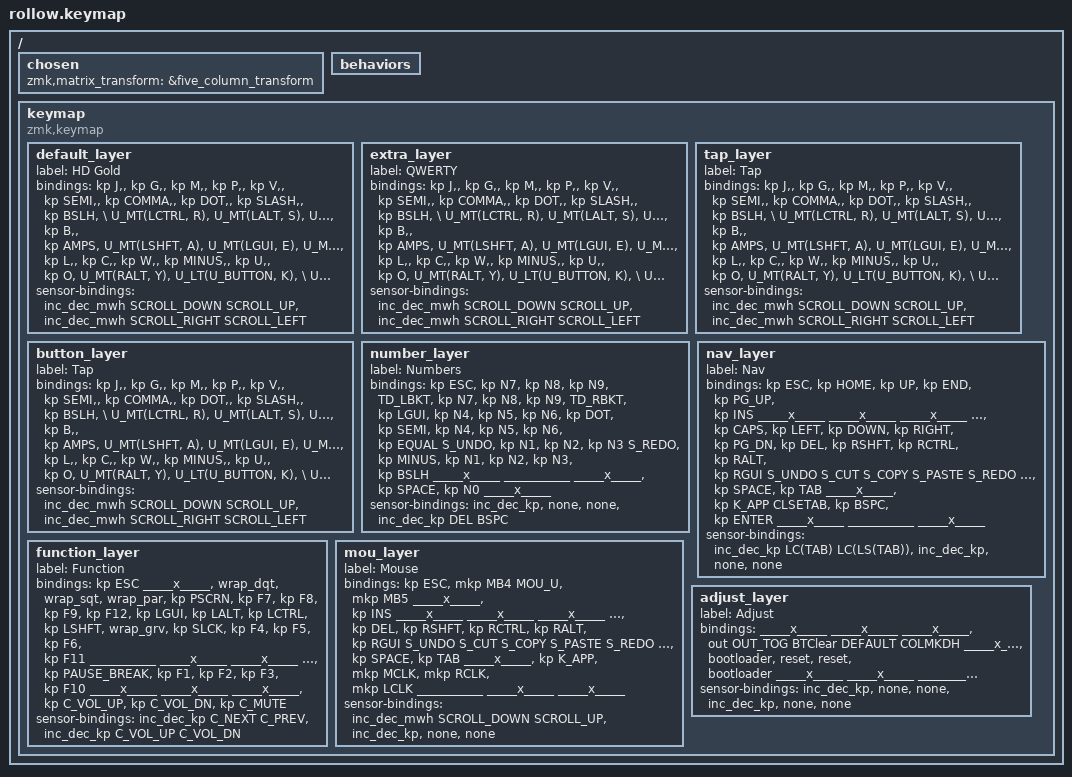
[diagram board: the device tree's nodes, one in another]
/*
 * Copyright (c) 2020 The ZMK Contributors
 *
 * SPDX-License-Identifier: MIT
 */

#include "../T4CORUN/t4corun.dtsi"

/ {
        chosen {
                zmk,matrix_transform = &five_column_transform;
	};

        behaviors {
        };


        keymap {
                compatible = "zmk,keymap";

                 /*
                 * Keyboard Layout:
                 *
                 * ,----------------------------------.                              ,----------------------------------.
                 * |      |      |      |      |      |                              |      |      |      |      |      |
                 * |------+------+------+------+------|                              |------+------+------+------+------|
                 * |      |      |      |      |      |                              |      |      |      |      |      | 
                 * |------+------+------+------+------|                              |------+------+------+------+------|
                 * |      |      |      |      |      |                              |      |      |      |      |      |
                 * `------+------+------+------|------.                              ,------|------+------+------+------'
                 *               |      |      |      |                              |      |      |      |
                 *               |      |      |      |                              |      |      |      |
                 *               |      |      |      |                              |      |      |      |
                 *               `--------------------'                              `--------------------'
                 */

                default_layer {

                /*
                * Base Layer: Hands Down Gold (Neu-tx)
                *
                * ,----------------------------------.                              ,----------------------------------.
                * |   J  |   G  |   M  |   P  |   V  |                              |  ; : |  , < |  . > | / ?  | \ |  |
                * |------+------+------+------+------|                              |------+------+------+------+------|
                * |   R  |   S  |   N  |   D  |   B  |                              |   &  |   A  |   E  |   I  |   H  | 
                * |------+------+------+------+------|                              |------+------+------+------+------|
                * |   X  |   F  |   L  |   C  |   W  |                              | - _  |   U  |   O  |   Y  |   K  |
                * `------+------+------+------|------.                              ,------|------+------+------+------'
                *               |PGUPDN|Bckspc|  T   |                              |Enter |Space |Vol   |
                *               |Esc   |SYM   | NAV  |                              |SYM   |NAV   |Delete|
                *               |NUM   |      |      |                              |      |      |FUN   |
                *               `--------------------'                              `--------------------'
                *
                *   Encoder Left: Up <-> Down
                *   Encoder Right: Left <-> Right
                */

                        label = "HD Gold";
                        
                        bindings = <
                                &kp J,             &kp G,             &kp M,             &kp P,             &kp V,             &kp SEMI,          &kp COMMA,         &kp DOT,           &kp SLASH,         &kp BSLH,            \
                                U_MT(LCTRL, R),    U_MT(LALT, S),     U_MT(LGUI, N),     U_MT(LSHFT, D),    &kp B,             &kp AMPS,          U_MT(LSHFT, A),    U_MT(LGUI, E),    U_MT(LALT, I),      U_MT(LCTRL, H),      \
                                U_LT(U_BUTTON, X), U_MT(RALT, F),     &kp L,             &kp C,             &kp W,             &kp MINUS,         &kp U,             &kp O,            U_MT(RALT, Y),      U_LT(U_BUTTON, K),   \
                                U_NP,              U_NP,              U_LT(U_FUN, DEL),  U_LT(U_NUM, BSPC), U_LT(U_SYM, T),  U_LT(U_MOUSE, TAB),U_LT(U_NAV, SPACE),U_LT(U_MEDIA, ESC),U_NP,              U_NP
                        >;

                        sensor-bindings = <&inc_dec_mwh SCROLL_DOWN SCROLL_UP &inc_dec_mwh SCROLL_RIGHT SCROLL_LEFT>;
                };

                extra_layer {

                /*
                * Extra Layer: QWERTY
                *
                * ,----------------------------------.                              ,----------------------------------.
                * |   Q  |   W  |   E  |   R  |   T  |                              |   Y  |   U  |   I  |   O  |   P  |
                * |------+------+------+------+------|                              |------+------+------+------+------|
                * |   A  |   S  |   D  |   F  |   G  |                              |   H  |   J  |   K  |   L  |   '  | 
                * |------+------+------+------+------|                              |------+------+------+------+------|
                * |   Z  |   X  |   C  |   V  |   B  |                              |   N  |   M  |   ,  |   .  | / BTN|
                * `------+------+------+------|------.                              ,------|------+------+------+------'
                *               | Esc  |Space | Tab  |                              |Enter |Bckspc|Delete|
                *               |MEDIA | NAV  |MOUSE |                              | SYM  | NUM  | FUN  |
                *               |      |      |      |                              |      |      |      |
                *               `--------------------'                              `--------------------'
                *
                *   Encoder Left: Up <-> Down
                *   Encoder Right: Left <-> Right
                */

                        label = "QWERTY";
                        
                        bindings = <
                                &kp J,             &kp G,             &kp M,             &kp P,             &kp V,             &kp SEMI,          &kp COMMA,         &kp DOT,           &kp SLASH,         &kp BSLH,            \
                                U_MT(LCTRL, R),    U_MT(LALT, S),     U_MT(LGUI, N),     U_MT(LSHFT, D),    &kp B,             &kp AMPS,          U_MT(LSHFT, A),    U_MT(LGUI, E),    U_MT(LALT, I),      U_MT(LCTRL, H),      \
                                U_LT(U_BUTTON, X), U_MT(RALT, F),     &kp L,             &kp C,             &kp W,             &kp MINUS,         &kp U,             &kp O,            U_MT(RALT, Y),      U_LT(U_BUTTON, K),   \
                                U_NP,              U_NP,              U_LT(U_FUN, DEL),  U_LT(U_NUM, BSPC), U_LT(U_SYM, T),  U_LT(U_MOUSE, TAB),U_LT(U_NAV, SPACE),U_LT(U_MEDIA, ESC),U_NP,              U_NP
                        >;

                        sensor-bindings = <&inc_dec_mwh SCROLL_DOWN SCROLL_UP &inc_dec_mwh SCROLL_RIGHT SCROLL_LEFT>;
                };


                tap_layer {

                /*
                * Tap Layer: Hands Down Gold (Neu-tx)
                *
                * ,----------------------------------.                              ,----------------------------------.
                * |   J  |   G  |   M  |   P  |   V  |                              |  ; : |  , < |  . > | / ?  | \ |  |
                * |------+------+------+------+------|                              |------+------+------+------+------|
                * |   R  |   S  |   N  |   D  |   B  |                              |   &  |   A  |   E  |   I  |   H  | 
                * |------+------+------+------+------|                              |------+------+------+------+------|
                * |   X  |   F  |   L  |   C  |   W  |                              | - _  |   U  |   O  |   Y  |   K  |
                * `------+------+------+------|------.                              ,------|------+------+------+------'
                *               |PGUPDN|Bckspc|  T   |                              |Enter |Space |Vol   |
                *               |Esc   |SYM   | NAV  |                              |SYM   |NAV   |Delete|
                *               |NUM   |      |      |                              |      |      |FUN   |
                *               `--------------------'                              `--------------------'
                */
                *   Encoder Left: Up <-> Down
                *   Encoder Right: Left <-> Right
                */

                        label = "Tap";
                        
                        bindings = <
                                &kp J,             &kp G,             &kp M,             &kp P,             &kp V,             &kp SEMI,          &kp COMMA,         &kp DOT,           &kp SLASH,         &kp BSLH,            \
                                U_MT(LCTRL, R),    U_MT(LALT, S),     U_MT(LGUI, N),     U_MT(LSHFT, D),    &kp B,             &kp AMPS,          U_MT(LSHFT, A),    U_MT(LGUI, E),    U_MT(LALT, I),      U_MT(LCTRL, H),      \
                                U_LT(U_BUTTON, X), U_MT(RALT, F),     &kp L,             &kp C,             &kp W,             &kp MINUS,         &kp U,             &kp O,            U_MT(RALT, Y),      U_LT(U_BUTTON, K),   \
                                U_NP,              U_NP,              U_LT(U_FUN, DEL),  U_LT(U_NUM, BSPC), U_LT(U_SYM, T),  U_LT(U_MOUSE, TAB),U_LT(U_NAV, SPACE),U_LT(U_MEDIA, ESC),U_NP,              U_NP
                        >;

                        sensor-bindings = <&inc_dec_mwh SCROLL_DOWN SCROLL_UP &inc_dec_mwh SCROLL_RIGHT SCROLL_LEFT>;
                };

                button_layer {

                /*
                * Button Layer: 
                *
                * ,----------------------------------.                              ,----------------------------------.
                * |   J  |   G  |   M  |   P  |   V  |                              |  ; : |  , < |  . > | / ?  | \ |  |
                * |------+------+------+------+------|                              |------+------+------+------+------|
                * |   R  |   S  |   N  |   D  |   B  |                              |   &  |   A  |   E  |   I  |   H  | 
                * |------+------+------+------+------|                              |------+------+------+------+------|
                * |   X  |   F  |   L  |   C  |   W  |                              | - _  |   U  |   O  |   Y  |   K  |
                * `------+------+------+------|------.                              ,------|------+------+------+------'
                *               |PGUPDN|Bckspc|  T   |                              |Enter |Space |Vol   |
                *               |Esc   |SYM   | NAV  |                              |SYM   |NAV   |Delete|
                *               |NUM   |      |      |                              |      |      |FUN   |
                *               `--------------------'                              `--------------------'
                */
                *   Encoder Left: Up <-> Down
                *   Encoder Right: Left <-> Right
                */

                        label = "Tap";
                        
                        bindings = <
                                &kp J,             &kp G,             &kp M,             &kp P,             &kp V,             &kp SEMI,          &kp COMMA,         &kp DOT,           &kp SLASH,         &kp BSLH,            \
                                U_MT(LCTRL, R),    U_MT(LALT, S),     U_MT(LGUI, N),     U_MT(LSHFT, D),    &kp B,             &kp AMPS,          U_MT(LSHFT, A),    U_MT(LGUI, E),    U_MT(LALT, I),      U_MT(LCTRL, H),      \
                                U_LT(U_BUTTON, X), U_MT(RALT, F),     &kp L,             &kp C,             &kp W,             &kp MINUS,         &kp U,             &kp O,            U_MT(RALT, Y),      U_LT(U_BUTTON, K),   \
                                U_NP,              U_NP,              U_LT(U_FUN, DEL),  U_LT(U_NUM, BSPC), U_LT(U_SYM, T),  U_LT(U_MOUSE, TAB),U_LT(U_NAV, SPACE),U_LT(U_MEDIA, ESC),U_NP,              U_NP
                        >;

                        sensor-bindings = <&inc_dec_mwh SCROLL_DOWN SCROLL_UP &inc_dec_mwh SCROLL_RIGHT SCROLL_LEFT>;
                };



                number_layer {

                /*
                * Number Layer: Numbers, symbols on shift
                *
                * ,----------------------------------.                              ,----------------------------------.
                * |      |  7 & | 8 *  | 9 (  |  }   |                              |      |ToBase|ToXtra|To Tap| Boot |
                * |------+------+------+------+------|                              |------+------+------+------+------|
                * |      |  4 $ | 5 %  | 6 ^  | + =  |                              |      |Shift | Gui  | Alt  |Ctrl  | 
                * |------+------+------+------+------|                              |------+------+------+------+------|
                * |      |  1 ! | 2 @  | 3 #  |      |                              |      |To Num|To Nav|AltGr |      |
                * `------+------+------+------+------|------.                ,------|------+------+------+-------------'
                *                      |      |      |      |                |      |      |      |
                *                      |      |  0 ) |      |                |      |      |      |
                *                      |      |      |      |                |      |      |      |
                *                      `--------------------'                `--------------------'
                *
                *   Encoder Left: x <-> x
                *   Encoder Right: Backspace <-> Del
                */

                        label = "Numbers";

                        bindings = <
                                &kp ESC         &kp N7          &kp N8          &kp N9          &TD_LBKT        &kp N7          &kp N8          &kp N9          &TD_RBKT
                                &kp LGUI        &kp N4          &kp N5          &kp N6          &kp DOT         &kp SEMI        &kp N4          &kp N5          &kp N6          &kp EQUAL
                                S_UNDO          &kp N1          &kp N2          &kp N3          S_REDO          &kp MINUS       &kp N1          &kp N2          &kp N3          &kp BSLH
                                                                _____x_____     ___________     _____x_____     &kp SPACE       &kp N0          _____x_____
                        >;

                        sensor-bindings = <&inc_dec_kp &none &none &inc_dec_kp DEL BSPC>;
                };

                nav_layer {

                /*
                 * NAV Layer: Navigation
                 *
                 * ,----------------------------------.                              ,----------------------------------.
                 * | Boot |To Tap|ToXtra|ToBase|      |                              |Again |Paste | Copy | Cut  | Undo |
                 * |------+------+------+------+------|                              |------+------+------+------+------|
                 * | Ctrl |  Alt | Gui  | Shift| Meta |                              |CapsLk| Left | Down |  Up  |Right | 
                 * |------+------+------+------+------|                              |------+------+------+------+------|
                 * |      |AltGr |To Num|To Nav|      |                              |Insert| Home |Pg Up |Pg Dn | End  |
                 * `------+------+------+------+------|------.                ,------|------+------+------+-------------'
                 *                      |      |      |      |                |Enter |Bckspc|Delete|
                 *                      |      |      |      |                |      |      |      |
                 *                      |      |      |      |                |      |      |      |
                 *                      `--------------------'                `--------------------'                            
                 */
                *   Encoder Left: Previous Browser Tab <-> Next Browser Tab
                *   Encoder Right: x <-> x
                */

                        label = "Nav";

                        bindings = <
                                &kp ESC         &kp HOME        &kp UP          &kp END         &kp PG_UP       &kp INS         _____x_____     _____x_____     _____x_____     _____x_____
                                &kp CAPS        &kp LEFT        &kp DOWN        &kp RIGHT       &kp PG_DN       &kp DEL         &kp RSHFT       &kp RCTRL       &kp RALT        &kp RGUI
                                S_UNDO          S_CUT           S_COPY          S_PASTE         S_REDO          _____x_____     &kp SPACE       &kp TAB         _____x_____     &kp K_APP
                                                                CLSETAB         &kp BSPC        &kp ENTER       _____x_____     ___________     _____x_____
                            >;

                        sensor-bindings = <&inc_dec_kp LC(TAB) LC(LS(TAB)) &inc_dec_kp &none &none>;
                };

                function_layer {

                /*
                *
                *   ,----------------------------------.    ,----------------------------------.
                *   | Esc  |      | wdqt | wsqt | wpar |    |PrtScr|  F7  |  F8  |  F9  | F12  |
                *   +------+------+------+------+------|    +------+------+------+------+------+
                *   | GUI  | Alt  | Ctrl | Shft | wgrv |    |ScrLck|  F4  |  F5  |  F6  | F11  |
                *   +------+------+------+------+------|    +------+------+------+------+------+
                *   |LyrTap|      |      |      |      |    |PauBrk|  F1  |  F2  |  F3  | F10  |
                *   `------+------+------+------+------+    +------+------+------+------+------'
                *                 |      |      |      |    | Vol- | Vol+ | mute |
                *                 `------+------+------'    `------+------+------'
                *
                *   Encoder Left: previous song <-> next song
                *   Encoder Right: Volume Down <-> Volume Up
                */

                        label = "Function";

                        bindings = <
                                &kp ESC         _____x_____     &wrap_dqt       &wrap_sqt       &wrap_par       &kp PSCRN       &kp F7          &kp F8          &kp F9          &kp F12
                                &kp LGUI        &kp LALT        &kp LCTRL       &kp LSHFT       &wrap_grv       &kp SLCK        &kp F4          &kp F5          &kp F6          &kp F11
                                ___________     _____x_____     _____x_____     _____x_____     _____x_____     &kp PAUSE_BREAK &kp F1          &kp F2          &kp F3          &kp F10
                                                                _____x_____     _____x_____     _____x_____     &kp C_VOL_UP    &kp C_VOL_DN    &kp C_MUTE
                        >;

                        sensor-bindings = <&inc_dec_kp C_NEXT C_PREV &inc_dec_kp C_VOL_UP C_VOL_DN>;
                };

                mou_layer {

                /*
                *
                *   ,----------------------------------.    ,----------------------------------.
                *   | Esc  | back | MouU | fwd  |      |    | Ins  |      |      |      |      |
                *   +------+------+------+------+------|    +------+------+------+------+------+
                *   |      | MouL | MouD | MouR |      |    | Del  | Shft | Ctrl | Alt  | GUI  |
                *   +------+------+------+------+------|    +------+------+------+------+------+
                *   | Undo | Cut  | Copy | Pste | Redo |    |      | Spc  | Tab  |      | App  |
                *   `------+------+------+------+------+    +------+------+------+------+------'
                *                 | MMB  | RMB  | LMB  |    |LyrTap|      |      |
                *                 `------+------+------'    `------+------+------'
                *
                *   Encoder Left: Previous Browser Tab <-> Next Browser Tab
                *   Encoder Right: x <-> x
                */

                        label = "Mouse";

                        bindings = <
                                &kp ESC         &mkp MB4        MOU_U           &mkp MB5        _____x_____     &kp INS         _____x_____     _____x_____     _____x_____     _____x_____
                                _____x_____     MOU_L           MOU_D           MOU_R           _____x_____     &kp DEL         &kp RSHFT       &kp RCTRL       &kp RALT        &kp RGUI
                                S_UNDO          S_CUT           S_COPY          S_PASTE         S_REDO          _____x_____     &kp SPACE       &kp TAB         _____x_____     &kp K_APP
                                                                &mkp MCLK       &mkp RCLK       &mkp LCLK       ___________     _____x_____     _____x_____
                            >;

                        sensor-bindings = <&inc_dec_mwh SCROLL_DOWN SCROLL_UP &inc_dec_kp &none &none>;
                };

                adjust_layer {

                /*
                *
                *   ,----------------------------------.    ,----------------------------------.
                *   |      |      |      |OutTog|BT Clr|    |QWERTY|CLMKDH|      |      |      |
                *   +------+------+------+------+------|    +------+------+------+------+------+
                *   | BT4  | BT3  | BT2  | BT1  | BT0  |    |      |      |      |      |      |
                *   +------+------+------+------+------|    +------+------+------+------+------+
                *   |      |      |      | boot |reset |    |reset |boot  |      |      |LyrTap|
                *   `------+------+------+------+------+    +------+------+------+------+------'
                *                 |      |      |      |    |      |      |      |
                *                 `------+------+------'    `------+------+------'
                *
                *   Encoder Left: x <-> x
                *   Encoder Right: x <-> x
                */

                        label = "Adjust";

                        bindings = <
                                _____x_____     _____x_____     _____x_____     &out OUT_TOG    BTClear         DEFAULT         COLMKDH         _____x_____     _____x_____     _____x_____
                                BT4             BT3             BT2             BT1             BT0             _____x_____     _____x_____     _____x_____     _____x_____     _____x_____
                                _____x_____     _____x_____     _____x_____     &bootloader     &reset          &reset          &bootloader     _____x_____     _____x_____     ___________
                                                                _____x_____     _____x_____     _____x_____     _____x_____     _____x_____     _____x_____
                        >;

                        sensor-bindings = <&inc_dec_kp &none &none &inc_dec_kp &none &none>;
                };
        };
};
